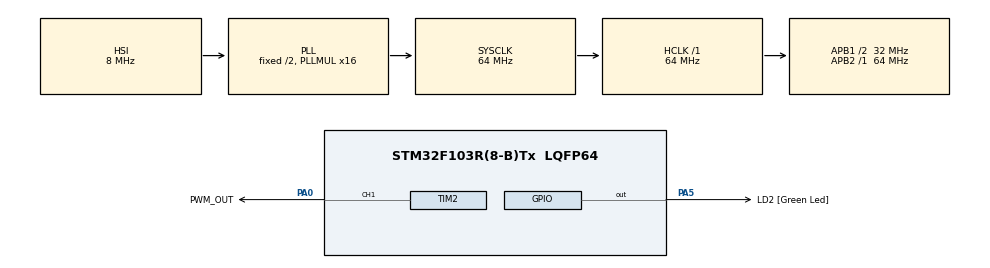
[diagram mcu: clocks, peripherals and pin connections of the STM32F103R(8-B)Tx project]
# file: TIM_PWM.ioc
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Mcu.Family=STM32F1
Mcu.Name=STM32F103R(8-B)Tx
Mcu.Package=LQFP64
NVIC.PriorityGroup=NVIC_PRIORITYGROUP_4
PA0-WKUP.GPIO_Label=PWM_OUT
PA0-WKUP.GPIO_Speed=GPIO_SPEED_FREQ_HIGH
PA0-WKUP.Signal=S_TIM2_CH1_ETR
PA13.GPIO_Label=TMS
PA13.Mode=Serial_Wire
PA13.Signal=SYS_JTMS-SWDIO
PA14.GPIO_Label=TCK
PA14.Mode=Serial_Wire
PA14.Signal=SYS_JTCK-SWCLK
PA5.GPIO_Label=LD2 [Green Led]
PA5.GPIO_ModeDefaultOutputPP=GPIO_MODE_OUTPUT_PP
PA5.GPIO_PuPd=GPIO_NOPULL
PA5.GPIO_Speed=GPIO_SPEED_FREQ_LOW
PA5.Signal=GPIO_Output
PB3.GPIO_Label=SWO
PB3.Signal=SYS_JTDO-TRACESWO
PC14-OSC32_IN.Mode=LSE-External-Oscillator
PC14-OSC32_IN.Signal=RCC_OSC32_IN
PC15-OSC32_OUT.Mode=LSE-External-Oscillator
PC15-OSC32_OUT.Signal=RCC_OSC32_OUT
PD0-OSC_IN.Mode=HSE-External-Clock-Source
PD0-OSC_IN.Signal=RCC_OSC_IN
PD1-OSC_OUT.Mode=HSE-External-Clock-Source
PD1-OSC_OUT.Signal=RCC_OSC_OUT
ProjectManager.HeapSize=0x200
ProjectManager.StackSize=0x400
ProjectManager.TargetToolchain=STM32CubeIDE
RCC.AHBFreq_Value=64000000
RCC.APB1CLKDivider=RCC_HCLK_DIV2
RCC.APB1Freq_Value=32000000
RCC.APB1TimFreq_Value=64000000
RCC.APB2Freq_Value=64000000
RCC.APB2TimFreq_Value=64000000
RCC.HCLKFreq_Value=64000000
RCC.PLLMUL=RCC_PLL_MUL16
RCC.RTCClockSelection=RCC_RTCCLKSOURCE_LSE
RCC.SYSCLKFreq_VALUE=64000000
RCC.SYSCLKSource=RCC_SYSCLKSOURCE_PLLCLK
RCC.USBFreq_Value=64000000
SH.S_TIM2_CH1_ETR.0=TIM2_CH1,PWM Generation1 CH1
TIM2.AutoReloadPreload=TIM_AUTORELOAD_PRELOAD_ENABLE
TIM2.Channel-PWM\ Generation1\ CH1=TIM_CHANNEL_1
TIM2.Period=999
TIM2.Prescaler=63
board=NUCLEO-F103RB

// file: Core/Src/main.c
/* USER CODE BEGIN Header */
/**
 ******************************************************************************
 * @file           : main.c
 * @brief          : Main program body
 ******************************************************************************
 * @attention
 *
 * Copyright (c) 2026 STMicroelectronics.
 * All rights reserved.
 *
 * This software is licensed under terms that can be found in the LICENSE file
 * in the root directory of this software component.
 * If no LICENSE file comes with this software, it is provided AS-IS.
 *
 ******************************************************************************
 */
/**
 * 02_TIM_PWM_c  —  [계층: HAL]  TIM2 CH1 PWM 출력 (LED 밝기 조절 / 서보 응용)
 *
 * 동작
 *   - TIM2_CH1(PA0 = Nucleo 'A0')에 1kHz PWM 출력, 듀티를 0~100% 왕복시켜 LED 를 숨쉬듯 점멸.
 *   - 회로: PA0 -> 저항(330Ω) -> 외부 LED -> GND
 *     (온보드 LD2 는 PA5 = TIM 채널이 아니므로 PWM 불가)
 *
 * PWM 주파수/듀티 계산
 *   TIM2 클럭 = 64MHz (APB1=32MHz, 분주비 != 1 이므로 타이머 클럭은 x2)
 *   PSC = 64-1   -> 카운터 클럭 1MHz  (TIM2->PSC)
 *   ARR = 1000-1 -> 주기 1000 카운트 = 1ms = 1kHz  (TIM2->ARR)
 *   CCR1 = 듀티(0~1000)  (TIM2->CCR1),  듀티% = CCR1 / (ARR+1) x 100
 *   CCMR1.OC1M = 110(PWM mode 1), CCER.CC1E = 1 (출력 활성)
 *
 * 서보 응용: PSC=64-1, ARR=20000-1 (20ms=50Hz), CCR1=1000~2000 (1~2ms 펄스)
 *
 * 이 예제는 인터럽트를 쓰지 않는다 (PWM 은 타이머 하드웨어가 파형을 생성).
 */
/* USER CODE END Header */
#include "main.h"

TIM_HandleTypeDef htim2;

void SystemClock_Config(void);
static void MX_GPIO_Init(void);
static void MX_TIM2_Init(void);

int main(void)
{

  /* USER CODE BEGIN 1 */
  int32_t duty = 0, step = 1;
  /* USER CODE END 1 */

  /* MCU Configuration--------------------------------------------------------*/

  /* Reset of all peripherals, Initializes the Flash interface and the Systick. */
  HAL_Init();

  /* Configure the system clock */
  SystemClock_Config();

  /* Initialize all configured peripherals */
  MX_GPIO_Init();
  MX_TIM2_Init();
  /* USER CODE BEGIN 2 */
  /* PWM 시작: TIM2->CCER.CC1E = 1 (CH1 출력 활성), TIM2->CR1.CEN = 1 (카운터 시작) */
  if (HAL_TIM_PWM_Start(&htim2, TIM_CHANNEL_1) != HAL_OK) Error_Handler();
  /* USER CODE END 2 */

  /* Infinite loop */
  while (1)
  {

    /* USER CODE BEGIN 3 */
    __HAL_TIM_SET_COMPARE(&htim2, TIM_CHANNEL_1, (uint32_t)duty);   /* TIM2->CCR1 = duty */

    duty += step;
    if (duty >= 999) step = -1;
    if (duty <= 0)   step = 1;
    HAL_Delay(1);                                                    /* 1ms x 1000 = 1초에 0->100% */
  }
  /* USER CODE END 3 */
}

void SystemClock_Config(void)
{
  RCC_OscInitTypeDef RCC_OscInitStruct = {0};
  RCC_ClkInitTypeDef RCC_ClkInitStruct = {0};

  /** Initializes the RCC Oscillators according to the specified parameters
  * in the RCC_OscInitTypeDef structure.
  */
  RCC_OscInitStruct.OscillatorType = RCC_OSCILLATORTYPE_HSI;
  RCC_OscInitStruct.HSIState = RCC_HSI_ON;
  RCC_OscInitStruct.HSICalibrationValue = RCC_HSICALIBRATION_DEFAULT;
  RCC_OscInitStruct.PLL.PLLState = RCC_PLL_ON;
  RCC_OscInitStruct.PLL.PLLSource = RCC_PLLSOURCE_HSI_DIV2;
  RCC_OscInitStruct.PLL.PLLMUL = RCC_PLL_MUL16;
  if (HAL_RCC_OscConfig(&RCC_OscInitStruct) != HAL_OK)
  {
    Error_Handler();
  }

  /** Initializes the CPU, AHB and APB buses clocks
  */
  RCC_ClkInitStruct.ClockType = RCC_CLOCKTYPE_HCLK|RCC_CLOCKTYPE_SYSCLK
                              |RCC_CLOCKTYPE_PCLK1|RCC_CLOCKTYPE_PCLK2;
  RCC_ClkInitStruct.SYSCLKSource = RCC_SYSCLKSOURCE_PLLCLK;
  RCC_ClkInitStruct.AHBCLKDivider = RCC_SYSCLK_DIV1;
  RCC_ClkInitStruct.APB1CLKDivider = RCC_HCLK_DIV2;
  RCC_ClkInitStruct.APB2CLKDivider = RCC_HCLK_DIV1;

  if (HAL_RCC_ClockConfig(&RCC_ClkInitStruct, FLASH_LATENCY_2) != HAL_OK)
  {
    Error_Handler();
  }
}

static void MX_TIM2_Init(void)
{

  TIM_MasterConfigTypeDef sMasterConfig = {0};
  TIM_OC_InitTypeDef sConfigOC = {0};

  htim2.Instance = TIM2;
  htim2.Init.Prescaler = 63;
  htim2.Init.CounterMode = TIM_COUNTERMODE_UP;
  htim2.Init.Period = 999;
  htim2.Init.ClockDivision = TIM_CLOCKDIVISION_DIV1;
  htim2.Init.AutoReloadPreload = TIM_AUTORELOAD_PRELOAD_ENABLE;
  if (HAL_TIM_PWM_Init(&htim2) != HAL_OK)
  {
    Error_Handler();
  }
  sMasterConfig.MasterOutputTrigger = TIM_TRGO_RESET;
  sMasterConfig.MasterSlaveMode = TIM_MASTERSLAVEMODE_DISABLE;
  if (HAL_TIMEx_MasterConfigSynchronization(&htim2, &sMasterConfig) != HAL_OK)
  {
    Error_Handler();
  }
  sConfigOC.OCMode = TIM_OCMODE_PWM1;
  sConfigOC.Pulse = 0;
  sConfigOC.OCPolarity = TIM_OCPOLARITY_HIGH;
  sConfigOC.OCFastMode = TIM_OCFAST_DISABLE;
  if (HAL_TIM_PWM_ConfigChannel(&htim2, &sConfigOC, TIM_CHANNEL_1) != HAL_OK)
  {
    Error_Handler();
  }
  /* USER CODE BEGIN TIM2_Init 2 */
  /* PSC=64-1 -> 1MHz, ARR=1000-1 -> 1kHz, CCR1 초기값 0 (CCMR1.OC1M=110 PWM1, CR1.ARPE=1) */
  /* USER CODE END TIM2_Init 2 */
  HAL_TIM_MspPostInit(&htim2);

}

static void MX_GPIO_Init(void)
{
  GPIO_InitTypeDef GPIO_InitStruct = {0};

  /* GPIO Ports Clock Enable */
  __HAL_RCC_GPIOC_CLK_ENABLE();
  __HAL_RCC_GPIOD_CLK_ENABLE();
  __HAL_RCC_GPIOA_CLK_ENABLE();
  __HAL_RCC_GPIOB_CLK_ENABLE();

  /*Configure GPIO pin Output Level */
  HAL_GPIO_WritePin(LD2_GPIO_Port, LD2_Pin, GPIO_PIN_RESET);

  /*Configure GPIO pin : LD2_Pin */
  GPIO_InitStruct.Pin = LD2_Pin;
  GPIO_InitStruct.Mode = GPIO_MODE_OUTPUT_PP;
  GPIO_InitStruct.Pull = GPIO_NOPULL;
  GPIO_InitStruct.Speed = GPIO_SPEED_FREQ_LOW;
  HAL_GPIO_Init(LD2_GPIO_Port, &GPIO_InitStruct);

}

void Error_Handler(void)
{
  __disable_irq();
  while (1) {
  }
}
#ifdef USE_FULL_ASSERT
/**
  * @brief  Reports the name of the source file and the source line number
  *         where the assert_param error has occurred.
  * @param  file: pointer to the source file name
  * @param  line: assert_param error line source number
  * @retval None
  */
void assert_failed(uint8_t *file, uint32_t line)
{
  /* USER CODE BEGIN 6 */
  /* User can add his own implementation to report the file name and line
     number, ex: printf("Wrong parameters value: file %s on line %d\r\n", file,
     line) */
  /* USER CODE END 6 */
}
#endif /* USE_FULL_ASSERT */
